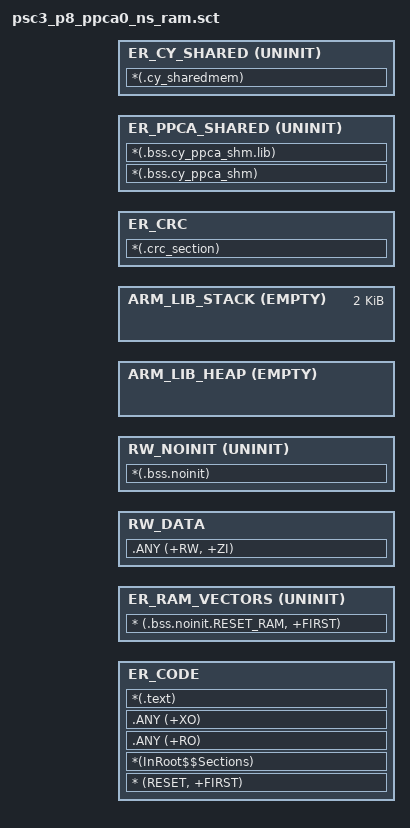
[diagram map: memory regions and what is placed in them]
#! armclang -E --target=arm-arm-none-eabi -x c -mcpu=cortex-m33
; The first line specifies a preprocessor command that the linker invokes
; to pass a scatter file through a C preprocessor.

;*******************************************************************************
;* \file ppca0_linker_ns_ram.sct
;* \version 1.000
;*
;* Linker file for the ARMCC.
;*
;* The main purpose of the linker script is to describe how the sections in the
;* input files should be mapped into the output file, and to control the memory
;* layout of the output file.
;*
;* \note The entry point location is fixed and starts at 0x12000000. The valid
;* application image should be placed there.
;*
;* \note The linker files included with the PDL template projects must be generic
;* and handle all common use cases. Your project may not use every section
;* defined in the linker files. In that case you may see warnings during the
;* build process. In your project, you can simply comment out or remove the
;* relevant code in the linker file.
;*******************************************************************************
;* \copyright
;* Copyright (c) (2024), Cypress Semiconductor Corporation (an Infineon company) or
;* an affiliate of Cypress Semiconductor Corporation.
;* SPDX-License-Identifier: Apache-2.0
;*
;* Licensed under the Apache License, Version 2.0 (the "License");
;* you may not use this file except in compliance with the License.
;* You may obtain a copy of the License at
;*
;*     http://www.apache.org/licenses/LICENSE-2.0
;*
;* Unless required by applicable law or agreed to in writing, software
;* distributed under the License is distributed on an "AS IS" BASIS,
;* WITHOUT WARRANTIES OR CONDITIONS OF ANY KIND, either express or implied.
;* See the License for the specific language governing permissions and
;* limitations under the License.
;******************************************************************************/

; Include the device memory definitions generated by the Device Configurator
#include "../config/GeneratedSource/cymem_armlink_CM33_1.sct"

; The size of the stack section at the end of CM33 SRAM 
#define RAMVECTORS_ALIGNMENT        512
;  2K for stack
#define STACK_SIZE  0x800

; Define symbols for the start and end of the CRC calculation range
#define __crc_start__ CYMEM_CM33_1_ppca0_code_START
#define __crc_end__   CYMEM_CM33_1_ppca0_crc_START

; Define the sections
LR_SRAM_CODE CYMEM_CM33_1_ppca0_code_START CYMEM_CM33_1_ppca0_code_SIZE
{
    ER_CODE (CYMEM_CM33_1_ppca0_code_START)
    {
        * (RESET, +FIRST)
        *(InRoot$$Sections)
        .ANY (+RO)
        .ANY (+XO)
        *(.text)
    }

    ER_RAM_VECTORS CYMEM_CM33_1_ppca0_data_START UNINIT
    {
        * (.bss.noinit.RESET_RAM, +FIRST)
    }

    RW_DATA +0
    {
        .ANY (+RW, +ZI)
    }

    RW_NOINIT +0 UNINIT
    {
        *(.bss.noinit)
    }

    ARM_LIB_HEAP  +0 EMPTY ((CYMEM_CM33_1_ppca0_data_START+CYMEM_CM33_1_ppca0_data_SIZE)-AlignExpr(ImageLimit(RW_NOINIT), 8)-STACK_SIZE)
    {
    }

    ARM_LIB_STACK (CYMEM_CM33_1_ppca0_data_START+CYMEM_CM33_1_ppca0_data_SIZE) EMPTY -STACK_SIZE
    {
    }
}
LR_SRAM_CRC CYMEM_CM33_1_ppca0_crc_START CYMEM_CM33_1_ppca0_crc_SIZE
{
    ER_CRC CYMEM_CM33_1_ppca0_crc_START
    {
        *(.crc_section)
    }
}
LR_SRAM_SHARED CYMEM_CM33_1_ppca_shm_data_START CYMEM_CM33_1_ppca_shm_data_SIZE
{
    ER_PPCA_SHARED CYMEM_CM33_1_ppca_shm_data_START UNINIT
    {
        *(.bss.cy_ppca_shm)
        *(.bss.cy_ppca_shm.lib)
    }

    ER_CY_SHARED AlignExpr(ImageLimit(ER_PPCA_SHARED), 4) UNINIT
    {
        *(.cy_sharedmem)
    }
}



/* [] END OF FILE */
